VERSION ""

NS_ :

BS_:

BU_: BCM Gateway

BO_ 100 BMS_status: 1 Gateway
 SG_ BODY_BMS_SOC : 0|1@1+ (1,0) [0|1] ""  BCM

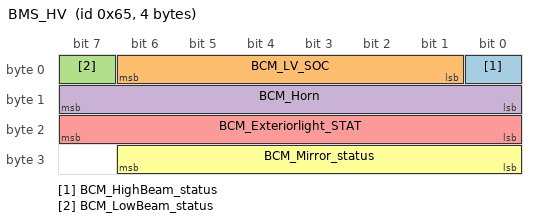
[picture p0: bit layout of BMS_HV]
BO_ 101 BMS_HV: 4 BCM
 SG_ BCM_HighBeam_status : 0|1@1+ (1,0) [0|1] ""  Gateway
 SG_ BCM_LV_SOC : 1|6@1+ (1,0) [0|100] ""  Gateway
 SG_ BCM_LowBeam_status : 7|1@1+ (1,0) [0|1] ""  Gateway
 SG_ BCM_Horn : 8|8@1+ (1,0) [0|1] ""  Gateway
 SG_ BCM_Exteriorlight_STAT : 16|8@1+ (1,0) [0|1] ""  Gateway
 SG_ BCM_Mirror_status : 24|7@1+ (1,0) [0|1] ""  Gateway
